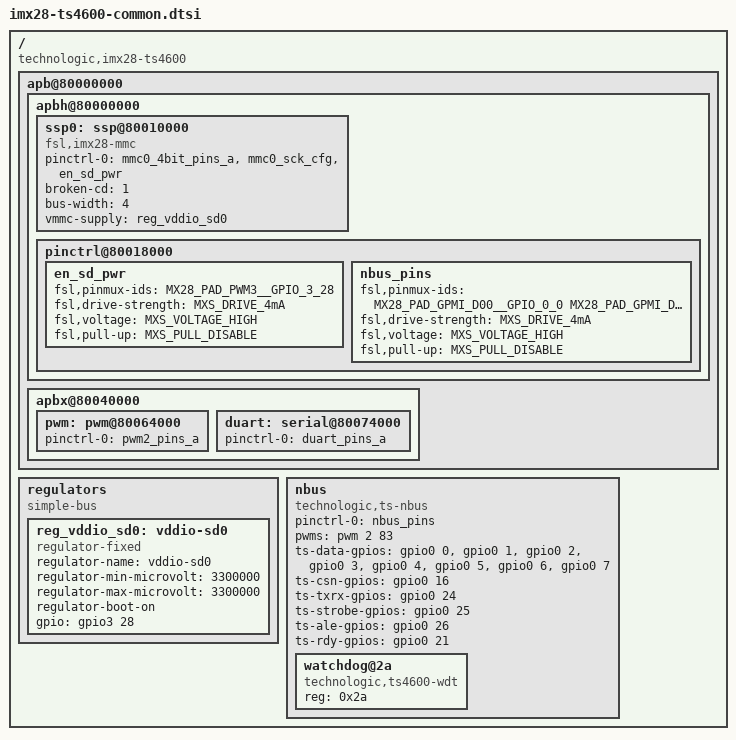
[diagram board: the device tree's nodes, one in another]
/*
 * Copyright (C) 2016 Savoir-Faire Linux
 * Author: Sebastien Bourdelin <sebastien.bourdelin@savoirfairelinux.com>
 *
 * The code contained herein is licensed under the GNU General Public
 * License. You may obtain a copy of the GNU General Public License
 * Version 2 or later at the following locations:
 *
 * http://www.opensource.org/licenses/gpl-license.html
 * http://www.gnu.org/copyleft/gpl.html
 */

/dts-v1/;
#include "imx28.dtsi"
#include "dt-bindings/gpio/gpio.h"

/ {

	compatible = "technologic,imx28-ts4600", "fsl,imx28";

	apb@80000000 {
		apbh@80000000 {
			ssp0: ssp@80010000 {
				compatible = "fsl,imx28-mmc";
				pinctrl-names = "default";
				pinctrl-0 = <&mmc0_4bit_pins_a
					     &mmc0_sck_cfg
					     &en_sd_pwr>;
				broken-cd = <1>;
				bus-width = <4>;
				vmmc-supply = <&reg_vddio_sd0>;
				status = "okay";
			};

			pinctrl@80018000 {
				pinctrl-names = "default";

				en_sd_pwr: en_sd_pwr {
					fsl,pinmux-ids = <
						MX28_PAD_PWM3__GPIO_3_28
					>;
					fsl,drive-strength = <MXS_DRIVE_4mA>;
					fsl,voltage = <MXS_VOLTAGE_HIGH>;
					fsl,pull-up = <MXS_PULL_DISABLE>;
				};

				nbus_pins: nbus_pins {
					fsl,pinmux-ids = <
						MX28_PAD_GPMI_D00__GPIO_0_0
						MX28_PAD_GPMI_D01__GPIO_0_1
						MX28_PAD_GPMI_D02__GPIO_0_2
						MX28_PAD_GPMI_D03__GPIO_0_3
						MX28_PAD_GPMI_D04__GPIO_0_4
						MX28_PAD_GPMI_D05__GPIO_0_5
						MX28_PAD_GPMI_D06__GPIO_0_6
						MX28_PAD_GPMI_D07__GPIO_0_7
						MX28_PAD_GPMI_CE0N__GPIO_0_16
						MX28_PAD_GPMI_RDY1__GPIO_0_21
						MX28_PAD_GPMI_RDN__GPIO_0_24
						MX28_PAD_GPMI_WRN__GPIO_0_25
						MX28_PAD_GPMI_ALE__GPIO_0_26
					>;
					fsl,drive-strength = <MXS_DRIVE_4mA>;
					fsl,voltage = <MXS_VOLTAGE_HIGH>;
					fsl,pull-up = <MXS_PULL_DISABLE>;

				};

			};
		};

		apbx@80040000 {
			pwm: pwm@80064000 {
				pinctrl-names = "default";
				pinctrl-0 = <&pwm2_pins_a>;
				status = "okay";
			};

			duart: serial@80074000 {
				pinctrl-names = "default";
				pinctrl-0 = <&duart_pins_a>;
				status = "okay";
			};
		};
	};

	regulators {
		compatible = "simple-bus";

		reg_vddio_sd0: vddio-sd0 {
			compatible = "regulator-fixed";
			regulator-name = "vddio-sd0";
			regulator-min-microvolt = <3300000>;
			regulator-max-microvolt = <3300000>;
			regulator-boot-on;
			gpio = <&gpio3 28 0>;
		};
	};

	nbus {
		compatible = "technologic,ts-nbus";
		pinctrl-0 = <&nbus_pins>;
		#address-cells = <1>;
		#size-cells = <0>;
		pwms = <&pwm 2 83>;
		ts-data-gpios   = <&gpio0 0 GPIO_ACTIVE_HIGH
				   &gpio0 1 GPIO_ACTIVE_HIGH
				   &gpio0 2 GPIO_ACTIVE_HIGH
				   &gpio0 3 GPIO_ACTIVE_HIGH
				   &gpio0 4 GPIO_ACTIVE_HIGH
				   &gpio0 5 GPIO_ACTIVE_HIGH
				   &gpio0 6 GPIO_ACTIVE_HIGH
				   &gpio0 7 GPIO_ACTIVE_HIGH>;
		ts-csn-gpios    = <&gpio0 16 GPIO_ACTIVE_HIGH>;
		ts-txrx-gpios   = <&gpio0 24 GPIO_ACTIVE_HIGH>;
		ts-strobe-gpios = <&gpio0 25 GPIO_ACTIVE_HIGH>;
		ts-ale-gpios    = <&gpio0 26 GPIO_ACTIVE_HIGH>;
		ts-rdy-gpios    = <&gpio0 21 GPIO_ACTIVE_HIGH>;

		watchdog@2a {
			compatible = "technologic,ts4600-wdt";
			reg = <0x2a>;
		};
	};

};
